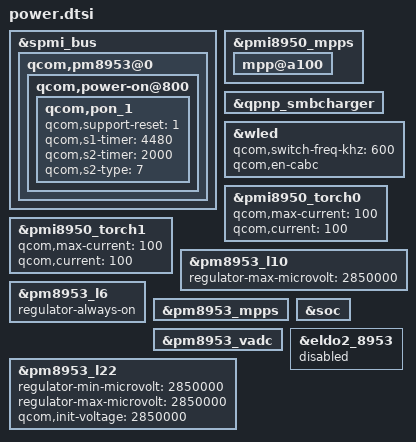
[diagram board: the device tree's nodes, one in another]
/* msm-pm8953.dtsi */
&spmi_bus {
	qcom,pm8953@0 {
		qcom,power-on@800 {
			qcom,pon_1 {
				qcom,support-reset = <1>;
				qcom,s1-timer = <4480>;
				qcom,s2-timer = <2000>;
				qcom,s2-type = <7>;
			};
		};
	};
};

/* msm-pmi8950.dtsi */
&pmi8950_mpps {
	mpp@a100 {
		status = "okay";
	};
};
&qpnp_smbcharger {
	/delete-property/ qcom,autoadjust-vfloat;
};
&wled {
	qcom,switch-freq-khz = <600>;
	/delete-property/ qcom,en-ext-pfet-sc-pro;
	qcom,en-cabc;
};
&pmi8950_torch0 {
	qcom,max-current = <100>;
	qcom,current = <100>;
};
&pmi8950_torch1 {
	qcom,max-current = <100>;
	qcom,current = <100>;
};

/* msm8953-oxygen.dtsi */
&pm8953_l10 {
	regulator-max-microvolt = <2850000>;
};
&pm8953_l6 {
	regulator-always-on;
};
&pm8953_mpps {
	/delete-node/ mpp@a100;
};
&pm8953_vadc {
	/delete-node/ chan@11;
};
/* msm8953-regulator.dtsi */
&pm8953_l22 {
	regulator-min-microvolt = <2850000>;
	regulator-max-microvolt = <2850000>;
	qcom,init-voltage = <2850000>;
};
&soc {
/* NOTE: eldo2 is used by tasha_codec in k4.9, but it's disabled */
/*
	/delete-node/ eldo2;
*/
};

/* Custom changes */
&eldo2_8953 { status = "disabled"; /delete-property/ gpio; };
